# RS1xxxx register map
Vendor: Silicon Lab Inc.; Series: ARMCM4; File version: 1.2
CPU: CM4 r1p0, little endian, MPU, FPU, 6 interrupt priority bits
Registers are 32-bit, read-write, reset 0x0 unless marked. A register's access mark holds for its fields unless they carry their own. Offsets are from the block's base; [hi:lo] are bit positions; 'fields as' and 'values as' point back to an identical list.

## QEI — The Quadrature Encoder Interface (QEI) module provides the interface to incremental encoders for obtaining mechanical position data
Base 0x47060000
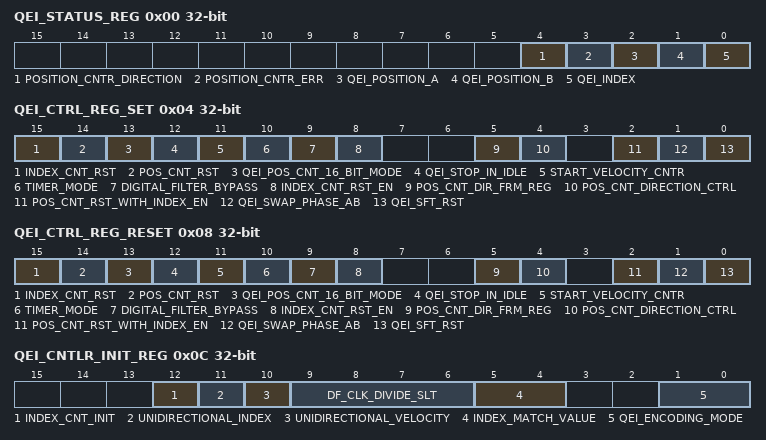
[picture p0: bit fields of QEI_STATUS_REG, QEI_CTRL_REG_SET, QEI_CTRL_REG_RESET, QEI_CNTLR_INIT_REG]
0x00 QEI_STATUS_REG ro — Quadrature Encoder status register
  [4] POSITION_CNTR_DIRECTION — Position Counter Direction Status bit
    0=Disable (Position counter direction is negative (-)); 1=Enable (Position counter direction is positive (+))
  [3] POSITION_CNTR_ERR — Count Error Status Flag bit
  [2] QEI_POSITION_A — This is a direct value from the position signal generator.Value refers to the signal Position_A from the generator.
  [1] QEI_POSITION_B — This is a direct value from the position signal generator.Value refers to the signal Position_B from the generator.
  [0] QEI_INDEX — This is a direct value from the position signal generator
0x04 QEI_CTRL_REG_SET — Quadrature Encoder control set register
  [15] INDEX_CNT_RST — 1= index counter is going to reset.
  [14] POS_CNT_RST — 1=position counter is going to reset
  [13] QEI_POS_CNT_16_BIT_MODE — Qei position counter 16 bit mode enable
    0=Disable (No effect); 1=Enable (QEI position status counter will be working as a 16 bit counter)
  [12] QEI_STOP_IN_IDLE
    0=Disable (QEI position status counter is working as 32 bit counter.); 1=Enable (QEI position status counter is working as 16 bit counter)
  [11] START_VELOCITY_CNTR — Starting the velocity counter. It is self reset bit.
  [10] TIMER_MODE
    0=Disable (Quadrature encoder mode); 1=Enable (timer mode. In this mode, decoded timer pulse and direction are taken from position A and position B pins respectively.)
  [9] DIGITAL_FILTER_BYPASS
    0=Disable (digital filter is in-path for all input signals); 1=Enable (digital filter is bypassed for all input signals (position A, position B and Index))
  [8] INDEX_CNT_RST_EN — Index count reset enable
    0=Disable (NONE); 1=Enable (index counter is going to reset after reaching max count, which is mentioned in qei_index_max_cnt register.)
  [5] POS_CNT_DIR_FRM_REG — Position Counter Direction indication from user
    values as QEI_STATUS_REG.POSITION_CNTR_DIRECTION
  [4] POS_CNT_DIRECTION_CTRL
    0=Disable (position B pin defines the direction of position counter); 1=Enable (pos_cnt_dir_frm_reg defines the position counter direction)
  [2] POS_CNT_RST_WITH_INDEX_EN — Phase A and Phase B Input Swap Select bit
    0=Disable (position counter is getting reset after reaching max count, which is mentioned in position_max_cnt); 1=Enable (position counter is getting reset for every index pulse)
  [1] QEI_SWAP_PHASE_AB — Phase A and Phase B Input Swap Select bit
    0=Disable (Phase A and Phase B inputs are not swapped); 1=Enable (Phase A and Phase B inputs are swapped)
  [0] QEI_SFT_RST ro — Quadrature encoder soft reset. It is self reset signal.
0x08 QEI_CTRL_REG_RESET — Quadrature Encoder control reset register
  [15] INDEX_CNT_RST — 1= index counter is going to reset.
  [14] POS_CNT_RST — 1=position counter is going to reset
  [13] QEI_POS_CNT_16_BIT_MODE — Qei position counter 16 bit mode enable
    values as QEI_CTRL_REG_SET.QEI_POS_CNT_16_BIT_MODE
  [12] QEI_STOP_IN_IDLE
    values as QEI_CTRL_REG_SET.QEI_STOP_IN_IDLE
  [11] START_VELOCITY_CNTR — Starting the velocity counter. It is self reset bit.
  [10] TIMER_MODE
    0=Disable (Quadrature encoder mode); 1=Enable (timer mode. In this mode, decoded timer pulse and direction are taken from position A and position B pins respectively)
  [9] DIGITAL_FILTER_BYPASS
    values as QEI_CTRL_REG_SET.DIGITAL_FILTER_BYPASS
  [8] INDEX_CNT_RST_EN
    values as QEI_CTRL_REG_SET.INDEX_CNT_RST_EN
  [5] POS_CNT_DIR_FRM_REG — Position Counter Direction indication from user
    values as QEI_STATUS_REG.POSITION_CNTR_DIRECTION
  [4] POS_CNT_DIRECTION_CTRL
    values as QEI_CTRL_REG_SET.POS_CNT_DIRECTION_CTRL
  [2] POS_CNT_RST_WITH_INDEX_EN — Phase A and Phase B Input Swap Select bit
    values as QEI_CTRL_REG_SET.POS_CNT_RST_WITH_INDEX_EN
  [1] QEI_SWAP_PHASE_AB — Phase A and Phase B Input Swap Select bit
    values as QEI_CTRL_REG_SET.QEI_SWAP_PHASE_AB
  [0] QEI_SFT_RST ro — Quadrature encoder soft reset. It is self reset signal
0x0C QEI_CNTLR_INIT_REG — Quadrature Encoder initialization register
  [12] INDEX_CNT_INIT — Index counter initial value in unidirectional index enable mode.
  [11] UNIDIRECTIONAL_INDEX — Uni directional index enable.
    0=Disable (NONE); 1=Enable (1 means direction change in position counter resets index counter)
  [10] UNIDIRECTIONAL_VELOCITY — Uni directional velocity enable.
    0=Disable (NONE); 1=Enable (1 means direction change in position counter resets velocity counter)
  [9:6] DF_CLK_DIVIDE_SLT — Digital Filter Clock Divide Select bits
    0=0000 = [1:1] Clock divide for Index, position A and B; 1=0001 = [1:2] Clock divide for Index, position A and B; 2=0010 = [1:4] Clock divide for Index, position A and B; 3=0011 = [1:8] Clock divide for Index, position A and B; 4=0100 = [1:16] Clock divide for Index, position A and B; 5=0101 = [1:32] Clock divide for Index, position A and B; 6=0110 = [1:6]4 Clock divide for Index, position A and B; 7=0111 = [1:12]8 Clock divide for Index, position A and B; 8=1000 = [1:25]6 Clock divide for Index, position A and B; 9=1001 = [1:5]12 Clock divide for Index, position A and B; 10=1010 = [1:10]24 Clock divide for Index, position A and B
  [5:4] INDEX_MATCH_VALUE — These bits allow user to specify the state of position A and B during index pulse generation.
  [1:0] QEI_ENCODING_MODE
    0=1x mode; 1=2x mode; 2=4x mode; 3=NONE
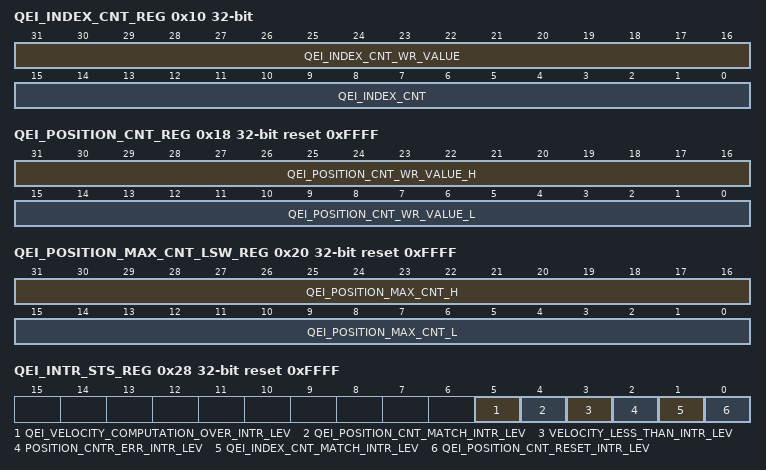
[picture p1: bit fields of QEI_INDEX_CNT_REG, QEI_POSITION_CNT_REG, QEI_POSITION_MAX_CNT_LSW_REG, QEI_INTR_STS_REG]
0x10 QEI_INDEX_CNT_REG (reset mask 0xFFFF) — Quadrature Encoder index counter register
  [31:16] QEI_INDEX_CNT_WR_VALUE — User can initialize/change the index counter using this register.
  [15:0] QEI_INDEX_CNT — Index counter value.User can initialize/change the index counter using this register
0x14 QEI_INDEX_MAX_CNT_REG reset 0xFFFF — Quadrature Encoder maximum index counter value register
  [15:0] QEI_INDEX_MAX_CNT — This is a maximum count value that is allowed to increment in the index counter. If index counter reaches this value, will get reset to zero
0x18 QEI_POSITION_CNT_REG reset 0xFFFF — Quadrature Encoder maximum position counter value register
  [31:16] QEI_POSITION_CNT_WR_VALUE_H — This is a maximum count value that is allowed to increment in the position counter.
  [15:0] QEI_POSITION_CNT_WR_VALUE_L — This is a maximum count value that is allowed to increment in the position counter.
0x20 QEI_POSITION_MAX_CNT_LSW_REG reset 0xFFFF — Quadrature Encoder maximum position counter value register
  [31:16] QEI_POSITION_MAX_CNT_H — This is a maximum count value that is allowed to increment in the position counter.
  [15:0] QEI_POSITION_MAX_CNT_L — This is a maximum count value that is allowed to increment in the position counter.
0x28 QEI_INTR_STS_REG ro reset 0xFFFF (reset mask 0x1F) — Quadrature Encoder interrupt status register
  [5] QEI_VELOCITY_COMPUTATION_OVER_INTR_LEV — When velocity count is computed for given delta time, than interrupt is raised.
  [4] QEI_POSITION_CNT_MATCH_INTR_LEV — This is raised when the position counter reaches position match value, which is programmable.
  [3] VELOCITY_LESS_THAN_INTR_LEV — When velocity count is less than the value given in velocity_value_to_compare register, interrupt is raised
  [2] POSITION_CNTR_ERR_INTR_LEV — Whenever number of possible positions are mismatched with actual positions are received between two index pulses this will raised
  [1] QEI_INDEX_CNT_MATCH_INTR_LEV — This is raised when index counter reaches max value loaded in to index_max_cnt register.
  [0] QEI_POSITION_CNT_RESET_INTR_LEV — This is raised when the position counter reaches it's extremes
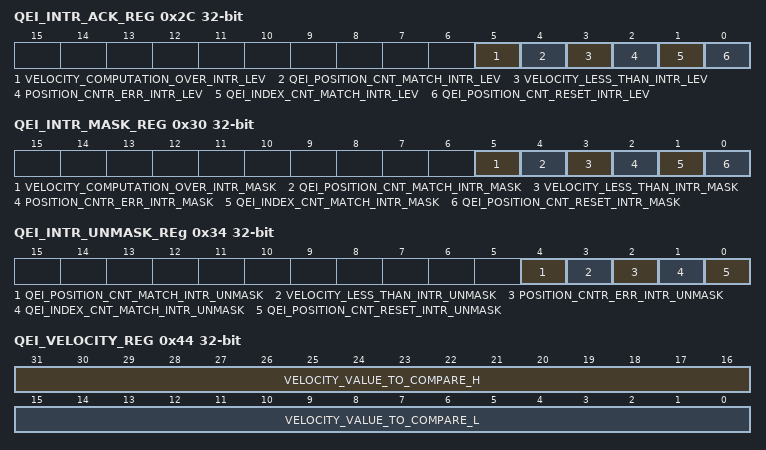
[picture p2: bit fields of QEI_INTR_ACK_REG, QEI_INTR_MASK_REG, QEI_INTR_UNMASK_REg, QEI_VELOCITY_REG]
0x2C QEI_INTR_ACK_REG (reset mask 0x1F) — Quadrature Encoder interrupt acknowledge register
  [5] VELOCITY_COMPUTATION_OVER_INTR_LEV — Velocity_computation_over_intr_ack
    0=Disable (No effect.); 1=Enable (Velocity computation is over intr will be cleared.)
  [4] QEI_POSITION_CNT_MATCH_INTR_LEV — Qei_position_cnt_match_intr_ack
    0=Disable (No effect.); 1=Enable (Qei position cnt match intr will be cleared.)
  [3] VELOCITY_LESS_THAN_INTR_LEV — Velocity_less_than_intr_ack
    0=Disable (No effect.); 1=Enable (Velocity less than intr will be cleared)
  [2] POSITION_CNTR_ERR_INTR_LEV — Position_cntr_err_intr_ack
    0=Disable (No effect.); 1=Enable (Position cntr err intr will be cleared.)
  [1] QEI_INDEX_CNT_MATCH_INTR_LEV
    0=Disable (No effect.); 1=Enable (Qei index cnt match intr will be cleared.)
  [0] QEI_POSITION_CNT_RESET_INTR_LEV — Qei_position_cnt_reset_intr_ack
    0=Disable (No effect.); 1=Enable (Qei position cnt reset intr will be cleared.)
0x30 QEI_INTR_MASK_REG (reset mask 0x1F) — Quadrature Encoder interrupt mask register
  [5] VELOCITY_COMPUTATION_OVER_INTR_MASK
    0=Disable (If read :Qei position cnt match intr is given on qei_intr pin If write: No effect); 1=Enable (If read :Qei position cnt match intr is given on qei_intr pin. If write:Qei position cnt match intr will not be given on qei_intr pin)
  [4] QEI_POSITION_CNT_MATCH_INTR_MASK
    values as VELOCITY_COMPUTATION_OVER_INTR_MASK
  [3] VELOCITY_LESS_THAN_INTR_MASK
    0=Disable (If read : Velocity less than intr is not given on qei_intr pin. If write: No effect); 1=Enable (If read :Velocity less than intr is given on qei_intr pin. If write: Velocity less than intr will not be given on qei_intr pin.)
  [2] POSITION_CNTR_ERR_INTR_MASK
    0=Disable (If read : Position cntr err intr is not given on qei_intr pin. If write: No effect); 1=Enable (If read : Position cntr err intr is given on qei_intr pin. If write: Position cntr err intr will not be given on qei_intr pin)
  [1] QEI_INDEX_CNT_MATCH_INTR_MASK
    0=Disable (If read : Qei index cnt match intr is not given on qei_intr pin If write: No effect); 1=Enable (If read : Qei index cnt match intr is given on qei_intr pin. If write: Qei index cnt match intr will not be given on qei_intr pin.)
  [0] QEI_POSITION_CNT_RESET_INTR_MASK
    0=Disable (If read : Qei position cnt reset intr is not given on qei_intr pin. If write: No effect); 1=Enable (If read : Qei position cnt reset intr is given on qei_intr pin If write: Qei position cnt reset intr will not be given on qei_intr pin)
0x34 QEI_INTR_UNMASK_REg — Quadrature Encoder interrupt unmask register
  [4] QEI_POSITION_CNT_MATCH_INTR_UNMASK
    values as QEI_INTR_MASK_REG.VELOCITY_COMPUTATION_OVER_INTR_MASK
  [3] VELOCITY_LESS_THAN_INTR_UNMASK
    values as QEI_INTR_MASK_REG.VELOCITY_LESS_THAN_INTR_MASK
  [2] POSITION_CNTR_ERR_INTR_UNMASK
    values as QEI_INTR_MASK_REG.POSITION_CNTR_ERR_INTR_MASK
  [1] QEI_INDEX_CNT_MATCH_INTR_UNMASK
    values as QEI_INTR_MASK_REG.QEI_INDEX_CNT_MATCH_INTR_MASK
  [0] QEI_POSITION_CNT_RESET_INTR_UNMASK
    values as QEI_INTR_MASK_REG.QEI_POSITION_CNT_RESET_INTR_MASK
0x38 QEI_CLK_FREQ_REG reset 0x27 (reset mask 0xFF) — Quadrature Encoder clock frequency register
  [8:0] QEI_CLK_FREQ — Indication of clock frequency on which QEI controller is running.
0x3C QEI_DELTA_TIME_REG reset 0x3E7 — Quadrature Delta time register
  [19:0] DELTA_TIME_FOR_VELOCITY — Delta time LSW to compute velocity
0x44 QEI_VELOCITY_REG — Quadrature velocity register
  [31:16] VELOCITY_VALUE_TO_COMPARE_H — For read operation :It is the velocity count to compare using TA firmware For write operation :It is the velocity value to compare with velocity count
  [15:0] VELOCITY_VALUE_TO_COMPARE_L — For read operation :It is the velocity count to compare using TA firmware For write operation :It is the velocity value to compare with velocity count
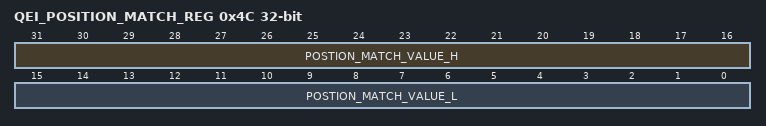
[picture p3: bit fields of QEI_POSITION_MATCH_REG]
0x4C QEI_POSITION_MATCH_REG — Quadrature position match register
  [31:16] POSTION_MATCH_VALUE_H — Position match value to compare the position counter.
  [15:0] POSTION_MATCH_VALUE_L — Position match value to compare the position counter.
